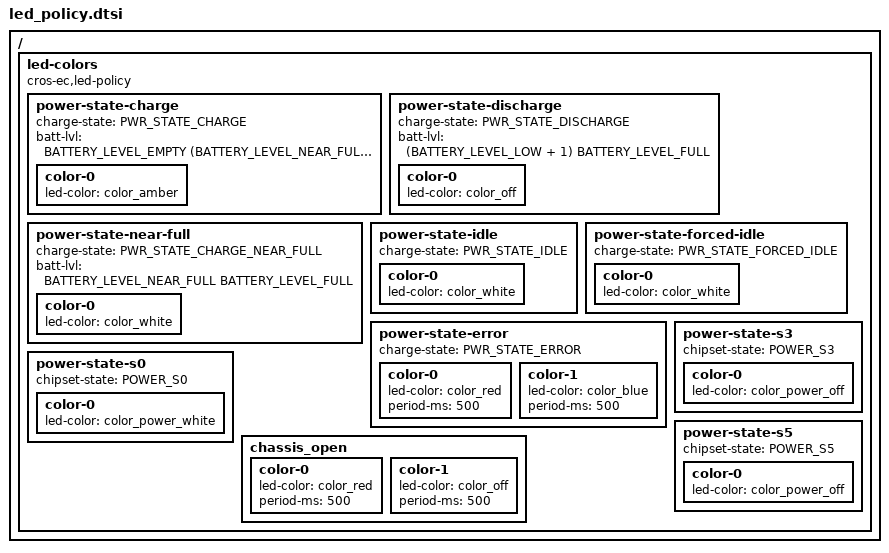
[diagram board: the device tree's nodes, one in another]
#include <dt-bindings/battery.h>

/ {
	led-colors {
		compatible = "cros-ec,led-policy";

		power-state-charge {
			charge-state = "PWR_STATE_CHARGE";
			/* Battery percent range (>= 0, <= 96) */
			batt-lvl = <BATTERY_LEVEL_EMPTY (BATTERY_LEVEL_NEAR_FULL-1)>;
			color-0 {
				led-color = <&color_amber>;
			};
		};

		power-state-discharge {
			charge-state = "PWR_STATE_DISCHARGE";
			/* Battery percent range (>= 11, <= 97) */
			batt-lvl = <(BATTERY_LEVEL_LOW + 1) BATTERY_LEVEL_FULL>;

			color-0 {
				led-color = <&color_off>;
			};
		};

		power-state-near-full {
			charge-state = "PWR_STATE_CHARGE_NEAR_FULL";
			/* Battery percent range (>= 97, <= 100) */
			batt-lvl = <BATTERY_LEVEL_NEAR_FULL BATTERY_LEVEL_FULL>;

			color-0 {
				led-color = <&color_white>;
			};
		};

		power-state-idle {
			charge-state = "PWR_STATE_IDLE";

			color-0 {
				led-color = <&color_white>;
			};
		};

		power-state-forced-idle {
			charge-state = "PWR_STATE_FORCED_IDLE";

			color-0 {
				led-color = <&color_white>;
			};
		};

		power-state-error {
			charge-state = "PWR_STATE_ERROR";

			color-0 {
				led-color = <&color_red>;
				period-ms = <500>;
			};
			color-1 {
				led-color = <&color_blue>;
				period-ms = <500>;
			};
		};

		power-state-s0 {
			chipset-state = "POWER_S0";

			color-0 {
				led-color = <&color_power_white>;
			};
		};

		power-state-s3 {
			chipset-state = "POWER_S3";

			color-0 {
				led-color = <&color_power_off>;
			};
		};

		power-state-s5 {
			chipset-state = "POWER_S5";

			color-0 {
				led-color = <&color_power_off>;
			};
		};

		chassis_open {
			color-0 {
				led-color = <&color_red>;
				period-ms = <500>;
			};
			color-1 {
				led-color = <&color_off>;
				period-ms = <500>;
			};
		};
	};
};
